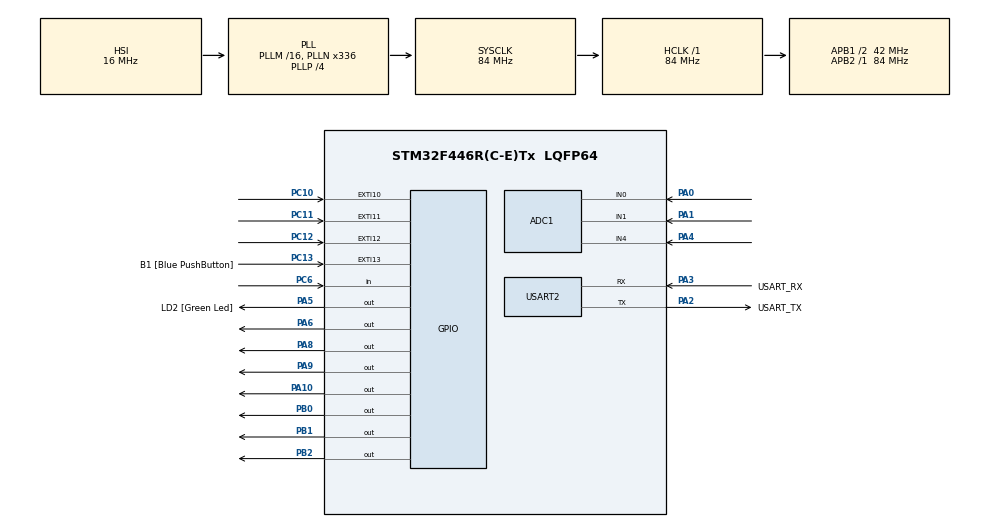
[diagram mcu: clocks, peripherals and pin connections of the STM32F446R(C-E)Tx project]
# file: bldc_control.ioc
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ADC1.Channel-0\#ChannelRegularConversion=ADC_CHANNEL_0
ADC1.NbrOfConversionFlag=1
ADC1.Rank-0\#ChannelRegularConversion=1
ADC1.SamplingTime-0\#ChannelRegularConversion=ADC_SAMPLETIME_3CYCLES
ADC1.master=1
Mcu.Family=STM32F4
Mcu.Name=STM32F446R(C-E)Tx
Mcu.Package=LQFP64
NVIC.EXTI15_10_IRQn=true\:5\:0\:true\:false\:true\:true\:true\:true
NVIC.PriorityGroup=NVIC_PRIORITYGROUP_4
PA0-WKUP.Signal=ADCx_IN0
PA1.Signal=ADCx_IN1
PA10.Signal=GPIO_Output
PA13.GPIO_Label=TMS
PA13.Mode=Serial_Wire
PA13.Signal=SYS_JTMS-SWDIO
PA14.GPIO_Label=TCK
PA14.Mode=Serial_Wire
PA14.Signal=SYS_JTCK-SWCLK
PA2.GPIO_Label=USART_TX
PA2.Mode=Asynchronous
PA2.Signal=USART2_TX
PA3.GPIO_Label=USART_RX
PA3.Mode=Asynchronous
PA3.Signal=USART2_RX
PA4.Signal=ADCx_IN4
PA5.GPIO_Label=LD2 [Green Led]
PA5.Signal=GPIO_Output
PA6.Signal=GPIO_Output
PA8.Signal=GPIO_Output
PA9.Signal=GPIO_Output
PB0.Signal=GPIO_Output
PB1.Signal=GPIO_Output
PB2.Signal=GPIO_Output
PB3.GPIO_Label=SWO
PB3.Signal=SYS_JTDO-SWO
PC10.GPIO_ModeDefaultEXTI=GPIO_MODE_IT_RISING_FALLING
PC10.GPIO_PuPd=GPIO_PULLDOWN
PC10.Signal=GPXTI10
PC11.GPIO_ModeDefaultEXTI=GPIO_MODE_IT_RISING_FALLING
PC11.GPIO_PuPd=GPIO_PULLDOWN
PC11.Signal=GPXTI11
PC12.GPIO_ModeDefaultEXTI=GPIO_MODE_IT_RISING_FALLING
PC12.GPIO_PuPd=GPIO_PULLDOWN
PC12.Signal=GPXTI12
PC13.GPIO_Label=B1 [Blue PushButton]
PC13.GPIO_ModeDefaultEXTI=GPIO_MODE_IT_FALLING
PC13.Signal=GPXTI13
PC14-OSC32_IN.Mode=LSE-External-Oscillator
PC14-OSC32_IN.Signal=RCC_OSC32_IN
PC15-OSC32_OUT.Mode=LSE-External-Oscillator
PC15-OSC32_OUT.Signal=RCC_OSC32_OUT
PC6.GPIO_PuPd=GPIO_PULLDOWN
PC6.Signal=GPIO_Input
PH0-OSC_IN.Mode=HSE-External-Oscillator
PH0-OSC_IN.Signal=RCC_OSC_IN
PH1-OSC_OUT.Mode=HSE-External-Oscillator
PH1-OSC_OUT.Signal=RCC_OSC_OUT
ProjectManager.HeapSize=0x200
ProjectManager.StackSize=0x400
ProjectManager.TargetToolchain=STM32CubeIDE
RCC.48MHZClocksFreq_Value=84000000
RCC.AHBFreq_Value=84000000
RCC.APB1CLKDivider=RCC_HCLK_DIV2
RCC.APB1Freq_Value=42000000
RCC.APB1TimFreq_Value=84000000
RCC.APB2Freq_Value=84000000
RCC.APB2TimFreq_Value=84000000
RCC.CortexFreq_Value=84000000
RCC.FLatency-AdvancedSettings=FLASH_LATENCY_2
RCC.HCLKFreq_Value=84000000
RCC.HSE_VALUE=8000000
RCC.HSI_VALUE=16000000
RCC.PLLN=336
RCC.PLLP=RCC_PLLP_DIV4
RCC.SYSCLKFreq_VALUE=84000000
RCC.SYSCLKSource=RCC_SYSCLKSOURCE_PLLCLK
RCC.USBFreq_Value=168000000
RCC.VCOOutputFreq_Value=336000000
SH.ADCx_IN0.0=ADC1_IN0,IN0
SH.ADCx_IN1.0=ADC1_IN1,IN1
SH.ADCx_IN4.0=ADC1_IN4,IN4
USART2.VirtualMode=VM_ASYNC
board=NUCLEO-F446RE

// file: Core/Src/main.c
/* USER CODE BEGIN Header */
/**
  ******************************************************************************
  * @file           : main.c
  * @brief          : Main program body
  ******************************************************************************
  * @attention
  *
  * Copyright (c) 2025 STMicroelectronics.
  * All rights reserved.
  *
  * This software is licensed under terms that can be found in the LICENSE file
  * in the root directory of this software component.
  * If no LICENSE file comes with this software, it is provided AS-IS.
  *
  ******************************************************************************
  */
/* USER CODE END Header */
#include "main.h"
#include "adc.h"
#include "usart.h"
#include "gpio.h"

/* USER CODE BEGIN Includes */
#include "six_step_logic.h"

/* USER CODE END Includes */

void SystemClock_Config(void);

int main(void)
{

  /* MCU Configuration--------------------------------------------------------*/

  /* Reset of all peripherals, Initializes the Flash interface and the Systick. */
  HAL_Init();

  /* Configure the system clock */
  SystemClock_Config();

  /* Initialize all configured peripherals */
  MX_GPIO_Init();
  MX_ADC1_Init();
  MX_USART2_UART_Init();
  /* USER CODE BEGIN 2 */
  disable_mosfets(); // stellt sicher, dass alle Halbbrücken am Anfang aus sind.

  /* USER CODE END 2 */

  /* Infinite loop */
  while (1)
  {

    /* USER CODE BEGIN 3 */

/* STATE MA CH IN E EEEEE */

  }

  /* USER CODE END 3 */
}

void SystemClock_Config(void)
{
  RCC_OscInitTypeDef RCC_OscInitStruct = {0};
  RCC_ClkInitTypeDef RCC_ClkInitStruct = {0};

  /** Configure the main internal regulator output voltage
  */
  __HAL_RCC_PWR_CLK_ENABLE();
  __HAL_PWR_VOLTAGESCALING_CONFIG(PWR_REGULATOR_VOLTAGE_SCALE3);

  /** Initializes the RCC Oscillators according to the specified parameters
  * in the RCC_OscInitTypeDef structure.
  */
  RCC_OscInitStruct.OscillatorType = RCC_OSCILLATORTYPE_HSI;
  RCC_OscInitStruct.HSIState = RCC_HSI_ON;
  RCC_OscInitStruct.HSICalibrationValue = RCC_HSICALIBRATION_DEFAULT;
  RCC_OscInitStruct.PLL.PLLState = RCC_PLL_ON;
  RCC_OscInitStruct.PLL.PLLSource = RCC_PLLSOURCE_HSI;
  RCC_OscInitStruct.PLL.PLLM = 16;
  RCC_OscInitStruct.PLL.PLLN = 336;
  RCC_OscInitStruct.PLL.PLLP = RCC_PLLP_DIV4;
  RCC_OscInitStruct.PLL.PLLQ = 2;
  RCC_OscInitStruct.PLL.PLLR = 2;
  if (HAL_RCC_OscConfig(&RCC_OscInitStruct) != HAL_OK)
  {
    Error_Handler();
  }

  /** Initializes the CPU, AHB and APB buses clocks
  */
  RCC_ClkInitStruct.ClockType = RCC_CLOCKTYPE_HCLK|RCC_CLOCKTYPE_SYSCLK
                              |RCC_CLOCKTYPE_PCLK1|RCC_CLOCKTYPE_PCLK2;
  RCC_ClkInitStruct.SYSCLKSource = RCC_SYSCLKSOURCE_PLLCLK;
  RCC_ClkInitStruct.AHBCLKDivider = RCC_SYSCLK_DIV1;
  RCC_ClkInitStruct.APB1CLKDivider = RCC_HCLK_DIV2;
  RCC_ClkInitStruct.APB2CLKDivider = RCC_HCLK_DIV1;

  if (HAL_RCC_ClockConfig(&RCC_ClkInitStruct, FLASH_LATENCY_2) != HAL_OK)
  {
    Error_Handler();
  }
}

/* USER CODE BEGIN 4 */

void HAL_GPIO_EXTI_Callback(uint16_t GPIO_Pin) {

	  // Timing-Pin HIGH (ISR start) PA6
	    GPIOA->BSRR = (1u << 6);

	 if (GPIO_Pin == GPIO_PIN_10 ||
	        GPIO_Pin == GPIO_PIN_11 ||
	        GPIO_Pin == GPIO_PIN_12)
	    {
	        // Deine ISR-Logik hier:
	        HAL_GPIO_TogglePin(GPIOA, GPIO_PIN_5);  // Beispiel: LED toggeln

	        six_step_sequence();
	    }

	 // Pin toggeln und dann messen wie lange die ISR dauert
	  // Timing-Pin LOW (ISR end)
	    GPIOA->BSRR = (1u << (6 + 16));
}

/* USER CODE END 4 */

void Error_Handler(void)
{
  __disable_irq();
  while (1)
  {
  }
}
